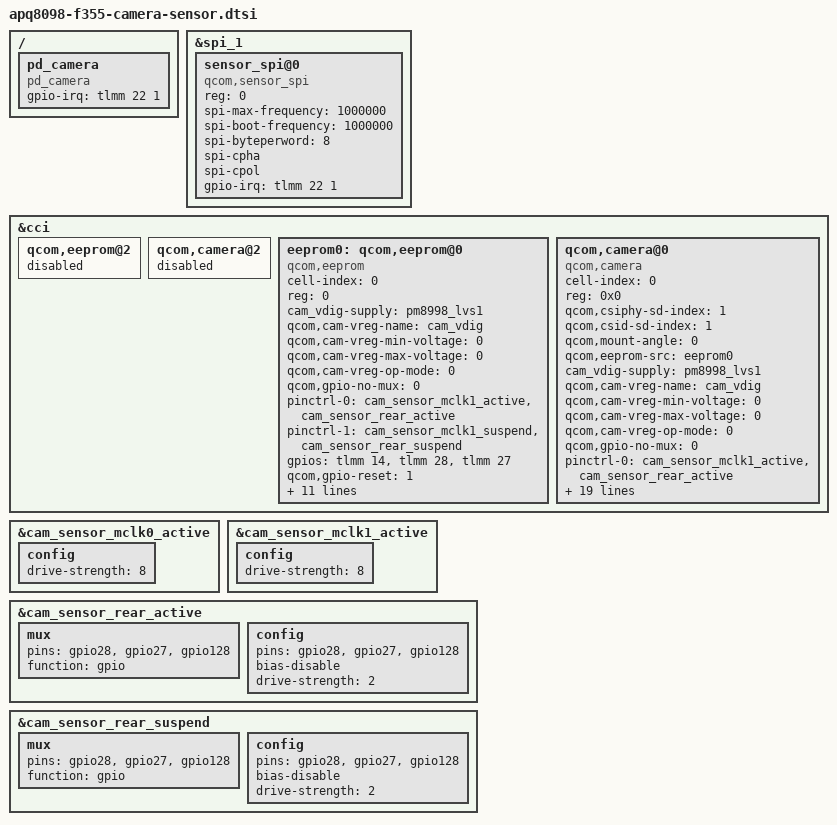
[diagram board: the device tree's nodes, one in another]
/* Copyright (c) 2017, Facebook Inc. All rights reserved.
 *
 * This program is free software; you can redistribute it and/or modify
 * it under the terms of the GNU General Public License version 2 and
 * only version 2 as published by the Free Software Foundation.
 *
 * This program is distributed in the hope that it will be useful,
 * but WITHOUT ANY WARRANTY; without even the implied warranty of
 * MERCHANTABILITY or FITNESS FOR A PARTICULAR PURPOSE.  See the
 * GNU General Public License for more details.
 */

/* Platform device for camera based presence detection */
/ {
	pd_camera: pd_camera {
		compatible = "pd_camera";
		gpio-irq = <&tlmm 22 1>;
	};
};

&spi_1 {
	sensor_spi@0 {
		compatible = "qcom,sensor_spi";
		reg = <0>; /* Chip select 0 */
		spi-max-frequency  = <1000000>;
		spi-boot-frequency = <1000000>;
		spi-byteperword = <8>;
		spi-cpha;
		spi-cpol;
		gpio-irq = <&tlmm 22 1>;
	};
};

/* Both claim gpio_28, but it's needed as IRQ for Myriad ISP */
&cci {
	qcom,eeprom@2 {
		status = "disabled";
	};

	qcom,camera@2 {
		status = "disabled";
	};
};

&cam_sensor_mclk0_active { /* MCLK0 */
	config {
		drive-strength = <8>; /* 8 MA */
	};
};

&cam_sensor_mclk1_active { /* MCLK1 */
	config {
		drive-strength = <8>; /* 8 MA */
	};
};

&cam_sensor_rear_active {
	/* RESET, STANDBY, CSI_SW_EN */
	mux {
		pins = "gpio28","gpio27","gpio128";
		function = "gpio";
	};

	config {
		pins = "gpio28","gpio27","gpio128";
		bias-disable; /* No PULL */
		drive-strength = <2>; /* 2 MA */
	};
};

&cam_sensor_rear_suspend {
	/* RESET, STANDBY, CSI_SW_EN */
	mux {
		pins = "gpio28","gpio27","gpio128";
		function = "gpio";
	};

	config {
		pins = "gpio28","gpio27","gpio128";
		bias-disable; /* No PULL */
		drive-strength = <2>; /* 2 MA */
	};
};

&cci {
	eeprom0: qcom,eeprom@0 {
		cell-index = <0>;
		reg = <0>;
		compatible = "qcom,eeprom";
		cam_vdig-supply = <&pm8998_lvs1>;
		qcom,cam-vreg-name = "cam_vdig";
		qcom,cam-vreg-min-voltage = <0>;
		qcom,cam-vreg-max-voltage = <0>;
		qcom,cam-vreg-op-mode = <0>;
		qcom,gpio-no-mux = <0>;
		pinctrl-names = "cam_default", "cam_suspend";
		pinctrl-0 = <	&cam_sensor_mclk1_active
				&cam_sensor_rear_active>;
		pinctrl-1 = <	&cam_sensor_mclk1_suspend
				&cam_sensor_rear_suspend>;
		gpios = <&tlmm 14 0>,
			<&tlmm 28 0>,
			<&tlmm 27 0>;
		qcom,gpio-reset = <1>;
		qcom,gpio-vana = <2>;
		qcom,gpio-req-tbl-num = <0 1 2>;
		qcom,gpio-req-tbl-flags = <1 0 0>;
		qcom,gpio-req-tbl-label = "CAMIF_MCLK1",
					"CAM_RESET1",
					"CAM_VANA";
		qcom,sensor-position = <0>;
		qcom,sensor-mode = <0>;
		qcom,cci-master = <1>;
		status = "ok";
		clocks = <&clock_mmss clk_mclk1_clk_src>,
				<&clock_mmss clk_mmss_camss_mclk1_clk>;
		clock-names = "cam_src_clk", "cam_clk";
		qcom,clock-rates = <24000000 0>;
	};

	qcom,camera@0 {
		cell-index = <0>;
		compatible = "qcom,camera";
		reg = <0x0>;
		qcom,csiphy-sd-index = <1>;
		qcom,csid-sd-index = <1>;
		qcom,mount-angle = <0>;
		qcom,eeprom-src = <&eeprom0>;
		cam_vdig-supply = <&pm8998_lvs1>;
		qcom,cam-vreg-name = "cam_vdig";
		qcom,cam-vreg-min-voltage = <0>;
		qcom,cam-vreg-max-voltage = <0>;
		qcom,cam-vreg-op-mode = <0>;
		qcom,gpio-no-mux = <0>;
		pinctrl-names = "cam_default", "cam_suspend";
		pinctrl-0 = <	&cam_sensor_mclk1_active
				&cam_sensor_rear_active>;
		pinctrl-1 = <	&cam_sensor_mclk1_suspend
				&cam_sensor_rear_suspend>;
		gpios = <&tlmm 14 0>,
			<&tlmm 28 0>,
			<&tlmm 27 0>,
			<&tlmm 128 0>;
		qcom,gpio-reset = <1>;
		qcom,gpio-vana = <2>;
		qcom,gpio-custom2 = <3>;
		qcom,gpio-req-tbl-num = <0 1 2 3>;
		qcom,gpio-req-tbl-flags = <1 0 0 0>;
		qcom,gpio-req-tbl-label = "CAMIF_MCLK1",
					"CAM_RESET1",
					"CAM_VANA",
					"CAM_V_CUSTOM2";
		qcom,sensor-position = <0>;
		qcom,sensor-mode = <0>;
		qcom,cci-master = <1>;
		status = "ok";
		clocks = <&clock_mmss clk_mclk1_clk_src>,
				<&clock_mmss clk_mmss_camss_mclk1_clk>;
		clock-names = "cam_src_clk", "cam_clk";
		qcom,clock-rates = <24000000 0>;
		qcom,cam-thermal;
		qcom,cam-temp-reg = <0x13A>;
		qcom,cam-temp-range = <(-20) 80>;
	};
};
